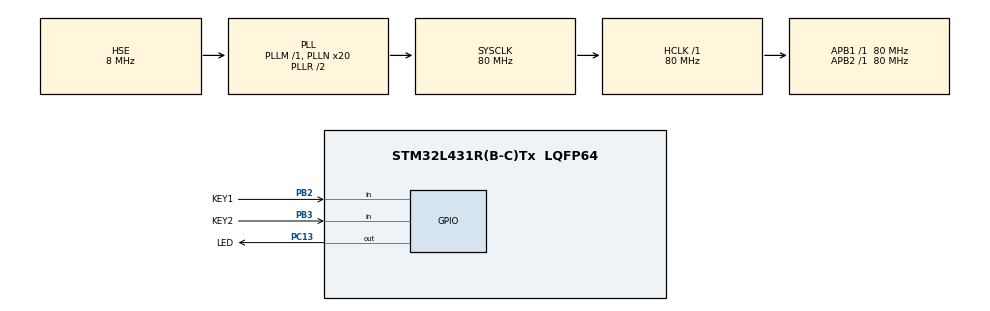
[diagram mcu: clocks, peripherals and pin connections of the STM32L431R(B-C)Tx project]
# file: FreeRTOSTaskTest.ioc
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FREERTOS.Tasks01=KEY_TASK,0,128,StartDefaultTask,Default,NULL,Dynamic,NULL,NULL;LED_TASK,-3,128,StartTask02,Default,NULL,Dynamic,NULL,NULL
Mcu.Family=STM32L4
Mcu.Name=STM32L431R(B-C)Tx
Mcu.Package=LQFP64
NVIC.PriorityGroup=NVIC_PRIORITYGROUP_4
NVIC.TIM1_UP_TIM16_IRQn=true\:0\:0\:false\:false\:true\:false\:false\:true
NVIC.TimeBase=TIM1_UP_TIM16_IRQn
NVIC.TimeBaseIP=TIM1
PB2.GPIO_Label=KEY1
PB2.GPIO_PuPd=GPIO_PULLUP
PB2.Signal=GPIO_Input
PB3\ (JTDO-TRACESWO).GPIO_Label=KEY2
PB3\ (JTDO-TRACESWO).GPIO_PuPd=GPIO_PULLUP
PB3\ (JTDO-TRACESWO).Signal=GPIO_Input
PC13.GPIO_Label=LED
PC13.Signal=GPIO_Output
PC14-OSC32_IN\ (PC14).Mode=LSE-External-Oscillator
PC14-OSC32_IN\ (PC14).Signal=RCC_OSC32_IN
PC15-OSC32_OUT\ (PC15).Mode=LSE-External-Oscillator
PC15-OSC32_OUT\ (PC15).Signal=RCC_OSC32_OUT
PH0-OSC_IN\ (PH0).Mode=HSE-External-Oscillator
PH0-OSC_IN\ (PH0).Signal=RCC_OSC_IN
PH1-OSC_OUT\ (PH1).Mode=HSE-External-Oscillator
PH1-OSC_OUT\ (PH1).Signal=RCC_OSC_OUT
ProjectManager.HeapSize=0x200
ProjectManager.StackSize=0x400
ProjectManager.TargetToolchain=SW4STM32
RCC.ADCFreq_Value=32000000
RCC.AHBFreq_Value=80000000
RCC.APB1Freq_Value=80000000
RCC.APB1TimFreq_Value=80000000
RCC.APB2Freq_Value=80000000
RCC.APB2TimFreq_Value=80000000
RCC.CortexFreq_Value=80000000
RCC.HCLKFreq_Value=80000000
RCC.HSE_VALUE=8000000
RCC.HSI48_VALUE=48000000
RCC.HSI_VALUE=16000000
RCC.MSI_VALUE=4000000
RCC.PLLN=20
RCC.PLLSourceVirtual=RCC_PLLSOURCE_HSE
RCC.SYSCLKFreq_VALUE=80000000
RCC.SYSCLKSource=RCC_SYSCLKSOURCE_PLLCLK
RCC.VCOOutputFreq_Value=160000000
VP_FREERTOS_VS_CMSIS_V1.Mode=CMSIS_V1
VP_SYS_VS_tim1.Mode=TIM1
board=custom

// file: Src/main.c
/* USER CODE BEGIN Header */
/**
  ******************************************************************************
  * @file           : main.c
  * @brief          : Main program body
  ******************************************************************************
  * @attention
  *
  * <h2><center>&copy; Copyright (c) 2020 STMicroelectronics.
  * All rights reserved.</center></h2>
  *
  * This software component is licensed by ST under Ultimate Liberty license
  * SLA0044, the "License"; You may not use this file except in compliance with
  * the License. You may obtain a copy of the License at:
  *                             www.st.com/SLA0044
  *
  ******************************************************************************
  */
/* USER CODE END Header */

#include "main.h"
#include "cmsis_os.h"
#include "gpio.h"

void SystemClock_Config(void);
void MX_FREERTOS_Init(void);

int main(void)
{

  /* MCU Configuration--------------------------------------------------------*/

  /* Reset of all peripherals, Initializes the Flash interface and the Systick. */
  HAL_Init();

  /* Configure the system clock */
  SystemClock_Config();

  /* Initialize all configured peripherals */
  MX_GPIO_Init();

  /* Call init function for freertos objects (in freertos.c) */
  MX_FREERTOS_Init();

  /* Start scheduler */
  osKernelStart();

  /* We should never get here as control is now taken by the scheduler */

  /* Infinite loop */
  while (1)
  {

  }
}

void SystemClock_Config(void)
{
  RCC_OscInitTypeDef RCC_OscInitStruct = {0};
  RCC_ClkInitTypeDef RCC_ClkInitStruct = {0};

  /** Initializes the CPU, AHB and APB busses clocks
  */
  RCC_OscInitStruct.OscillatorType = RCC_OSCILLATORTYPE_HSE;
  RCC_OscInitStruct.HSEState = RCC_HSE_ON;
  RCC_OscInitStruct.PLL.PLLState = RCC_PLL_ON;
  RCC_OscInitStruct.PLL.PLLSource = RCC_PLLSOURCE_HSE;
  RCC_OscInitStruct.PLL.PLLM = 1;
  RCC_OscInitStruct.PLL.PLLN = 20;
  RCC_OscInitStruct.PLL.PLLP = RCC_PLLP_DIV7;
  RCC_OscInitStruct.PLL.PLLQ = RCC_PLLQ_DIV2;
  RCC_OscInitStruct.PLL.PLLR = RCC_PLLR_DIV2;
  if (HAL_RCC_OscConfig(&RCC_OscInitStruct) != HAL_OK)
  {
    Error_Handler();
  }
  /** Initializes the CPU, AHB and APB busses clocks
  */
  RCC_ClkInitStruct.ClockType = RCC_CLOCKTYPE_HCLK|RCC_CLOCKTYPE_SYSCLK
                              |RCC_CLOCKTYPE_PCLK1|RCC_CLOCKTYPE_PCLK2;
  RCC_ClkInitStruct.SYSCLKSource = RCC_SYSCLKSOURCE_PLLCLK;
  RCC_ClkInitStruct.AHBCLKDivider = RCC_SYSCLK_DIV1;
  RCC_ClkInitStruct.APB1CLKDivider = RCC_HCLK_DIV1;
  RCC_ClkInitStruct.APB2CLKDivider = RCC_HCLK_DIV1;

  if (HAL_RCC_ClockConfig(&RCC_ClkInitStruct, FLASH_LATENCY_4) != HAL_OK)
  {
    Error_Handler();
  }
  /** Configure the main internal regulator output voltage
  */
  if (HAL_PWREx_ControlVoltageScaling(PWR_REGULATOR_VOLTAGE_SCALE1) != HAL_OK)
  {
    Error_Handler();
  }
}

void HAL_TIM_PeriodElapsedCallback(TIM_HandleTypeDef *htim)
{
  if (htim->Instance == TIM1) {
    HAL_IncTick();
  }
}

void Error_Handler(void)
{
}

/************************ (C) COPYRIGHT STMicroelectronics *****END OF FILE****/

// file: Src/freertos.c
/* USER CODE BEGIN Header */
/**
  ******************************************************************************
  * File Name          : freertos.c
  * Description        : Code for freertos applications
  ******************************************************************************
  * @attention
  *
  * <h2><center>&copy; Copyright (c) 2020 STMicroelectronics.
  * All rights reserved.</center></h2>
  *
  * This software component is licensed by ST under Ultimate Liberty license
  * SLA0044, the "License"; You may not use this file except in compliance with
  * the License. You may obtain a copy of the License at:
  *                             www.st.com/SLA0044
  *
  ******************************************************************************
  */
/* USER CODE END Header */

#include "FreeRTOS.h"
#include "task.h"
#include "main.h"
#include "cmsis_os.h"

osThreadId KEY_TASKHandle;
osThreadId LED_TASKHandle;

void StartDefaultTask(void const * argument);
void StartTask02(void const * argument);

void MX_FREERTOS_Init(void); /* (MISRA C 2004 rule 8.1) */

/* GetIdleTaskMemory prototype (linked to static allocation support) */
void vApplicationGetIdleTaskMemory( StaticTask_t **ppxIdleTaskTCBBuffer, StackType_t **ppxIdleTaskStackBuffer, uint32_t *pulIdleTaskStackSize );

/* USER CODE BEGIN GET_IDLE_TASK_MEMORY */
static StaticTask_t xIdleTaskTCBBuffer;
static StackType_t xIdleStack[configMINIMAL_STACK_SIZE];

void vApplicationGetIdleTaskMemory( StaticTask_t **ppxIdleTaskTCBBuffer, StackType_t **ppxIdleTaskStackBuffer, uint32_t *pulIdleTaskStackSize )
{
  *ppxIdleTaskTCBBuffer = &xIdleTaskTCBBuffer;
  *ppxIdleTaskStackBuffer = &xIdleStack[0];
  *pulIdleTaskStackSize = configMINIMAL_STACK_SIZE;
  /* place for user code */
}
/* USER CODE END GET_IDLE_TASK_MEMORY */

void MX_FREERTOS_Init(void) {

  /* Create the thread(s) */
  /* definition and creation of KEY_TASK */
  osThreadDef(KEY_TASK, StartDefaultTask, osPriorityNormal, 0, 128);
  KEY_TASKHandle = osThreadCreate(osThread(KEY_TASK), NULL);

  /* definition and creation of LED_TASK */
  osThreadDef(LED_TASK, StartTask02, osPriorityNormal, 0, 128);
  LED_TASKHandle = osThreadCreate(osThread(LED_TASK), NULL);

}

void StartDefaultTask(void const * argument)
{
  /* USER CODE BEGIN StartDefaultTask */
  /* Infinite loop */
  for(;;)
  {
    if(HAL_GPIO_ReadPin(KEY1_GPIO_Port, KEY1_Pin) == GPIO_PIN_RESET){
        vTaskSuspend(LED_TASKHandle);
    }
    if(HAL_GPIO_ReadPin(KEY2_GPIO_Port, KEY2_Pin) == GPIO_PIN_RESET){
        vTaskResume(LED_TASKHandle);
    }
    osDelay(20);
  }
  /* USER CODE END StartDefaultTask */
}

void StartTask02(void const * argument)
{
  /* USER CODE BEGIN StartTask02 */
  /* Infinite loop */
  for(;;)
  {
    HAL_GPIO_TogglePin(LED_GPIO_Port, LED_Pin);
    osDelay(1000);
  }
  /* USER CODE END StartTask02 */
}

/************************ (C) COPYRIGHT STMicroelectronics *****END OF FILE****/
